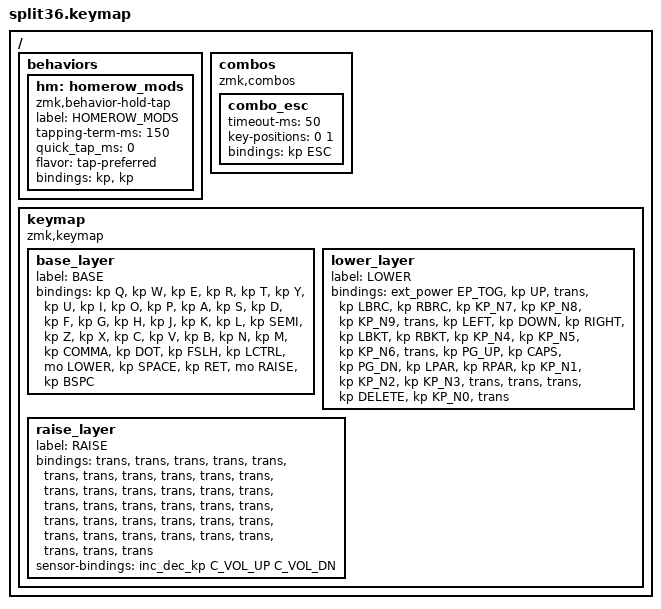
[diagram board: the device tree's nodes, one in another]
#include <behaviors.dtsi>
#include <dt-bindings/zmk/keys.h>
#include <dt-bindings/zmk/bt.h>
#include <dt-bindings/zmk/outputs.h>
#include <dt-bindings/zmk/ext_power.h>

#define BASE   0
#define LOWER  1
#define RAISE  2


/ {
    behaviors {
        hm: homerow_mods {
            compatible = "zmk,behavior-hold-tap";
            label = "HOMEROW_MODS";
            #binding-cells = <2>;
            tapping-term-ms = <150>;
            quick_tap_ms = <0>;
            flavor = "tap-preferred";
            bindings = <&kp>, <&kp>;
        };

    };

    combos {
            compatible = "zmk,combos";
            combo_esc {
                timeout-ms = <50>;
                key-positions = <0 1>;
                bindings = <&kp ESC>;
            };
    };



    keymap {
                compatible = "zmk,keymap";
                base_layer {
label= "BASE";
/*           ┌─────────┬─────────┬─────────┬─────────┬─────────┐                    ┌─────────┬─────────┬─────────┬─────────┬─────────┐
             │    Q    │    W    │    E    │    R    │    T    │                    │    Y    │    U    │    I    │    O    │    P    │   
             ├─────────┼─────────┼─────────┼─────────┼─────────┤                    ├─────────┼─────────┼─────────┼─────────┼─────────┤
             │    A    │    S    │    D    │    F    │    G    │                    │    H    │    J    │    K    │    L    │    ;    │
             ├─────────┼─────────┼─────────┼─────────┼─────────┤                    ├─────────┼─────────┼─────────┼─────────┼─────────┤
             │    Z    │    X    │    C    │    V    │    B    │                    │    N    │    M    │    ,    │    .    │    /    │
             └─────────┴─────────┼─────────┼─────────┼─────────┼─────────┐┌─────────┼─────────┼─────────┼─────────┼─────────┴─────────┘
                                           │  CTRL   │  LOWER  │  SPACE  ││   RET   │  RAISE  │  BSPCE  │            
                                           ┴─────────┴─────────┴─────────┘└─────────┴─────────┴─────────┴           */ 
 bindings = <
 // &hm RSHIFT J
 //          ╷         ╷         ╷         ╷         ╷         ╷         ╷╷         ╷         ╷         ╷         ╷         ╷         ╷         ╷
              &kp Q     &kp W     &kp E     &kp R     &kp T                          &kp Y     &kp U     &kp I     &kp O     &kp P
              &kp A     &kp S     &kp D     &kp F     &kp G                          &kp H     &kp J     &kp K     &kp L     &kp SEMI
              &kp Z     &kp X     &kp C     &kp V     &kp B                          &kp N     &kp M     &kp COMMA &kp DOT   &kp FSLH
                                         &kp LCTRL &mo LOWER &kp SPACE     &kp RET   &mo RAISE &kp BSPC
                        >;
                };

                lower_layer {
label= "LOWER";
/*           ┌─────────┬─────────┬─────────┬─────────┬─────────┐                    ┌─────────┬─────────┬─────────┬─────────┬─────────┐
             │ EP_TOG  │         │    UP   │         │    {    │                    │    }    │    7    │    8    │    9    │    +    │
             ┼─────────┼─────────┼─────────┼─────────┼─────────┤                    ├─────────┼─────────┼─────────┼─────────┼─────────┼          
             │         │   LEFT  │  DOWN   │  RIGHT  │    [    │                    │    ]    │    4    │    5    │    6    │    -    │          
             ┼─────────┼─────────┼─────────┼─────────┼─────────┤                    ├─────────┼─────────┼─────────┼─────────┼─────────┼          
             │         │   P UP  │ C LOCK  │ P DOWN  │    (    │                    │    )    │    1    │    2    │    3    │    *    │          
             ┴─────────┴─────────┼─────────┼─────────┼─────────┼                    ┼─────────┼─────────┼─────────┼─────────┴─────────┴          
                                 │         │         │         │         ││         │         │    0    │         │  
                                 └─────────┴─────────┴─────────┴─────────┘└─────────┴─────────┴─────────┴─────────┘ */ 
 bindings = <
 //          ╷         ╷         ╷         ╷         ╷         ╷         ╷╷         ╷         ╷         ╷         ╷         ╷         ╷         ╷
               &ext_power EP_TOG  &kp UP    &trans    &kp LBRC                       &kp RBRC  &kp KP_N7 &kp KP_N8 &kp KP_N9
              &trans    &kp LEFT  &kp DOWN  &kp RIGHT &kp LBKT                       &kp RBKT  &kp KP_N4 &kp KP_N5 &kp KP_N6
              &trans    &kp PG_UP &kp CAPS  &kp PG_DN &kp LPAR                       &kp RPAR  &kp KP_N1 &kp KP_N2 &kp KP_N3
                                              &trans    &trans   &trans   &kp DELETE &kp KP_N0 &trans  
                        >;
                };
		
		raise_layer {
label= "RAISE";
/*
             ┼─────────┼─────────┼─────────┼─────────┼─────────┤                    ├─────────┼─────────┼─────────┼─────────┼─────────┼
             │         │    ß    │         │         │         │                    │         │         │         │         │    Ö    │
             ┼─────────┼─────────┼─────────┼─────────┼─────────┤                    ├─────────┼─────────┼─────────┼─────────┼─────────┼
             │         │         │         │         │         │                    │         │         │         │         │         │
             ┴─────────┴─────────┼─────────┼─────────┼─────────┼                    ┼─────────┼─────────┼─────────┼─────────┴─────────┴
                                           │         │         │         ││         │         │         │            
                                           ┴─────────┴─────────┴─────────┘└─────────┴─────────┴─────────┴           */ 
 bindings = <
 //╷         ╷         ╷         ╷         ╷         ╷         ╷         ╷╷         ╷         ╷         ╷         ╷         ╷         ╷         ╷
              &trans    &trans    &trans    &trans    &trans                         &trans    &trans    &trans    &trans    &trans
              &trans    &trans    &trans    &trans    &trans                         &trans    &trans    &trans    &trans    &trans
              &trans    &trans    &trans    &trans    &trans    &trans     &trans    &trans    &trans    &trans    &trans    &trans
                                            &trans    &trans    &trans     &trans    &trans    &trans
                        >;
                sensor-bindings = <&inc_dec_kp C_VOL_UP C_VOL_DN>;
                };
	};
};
